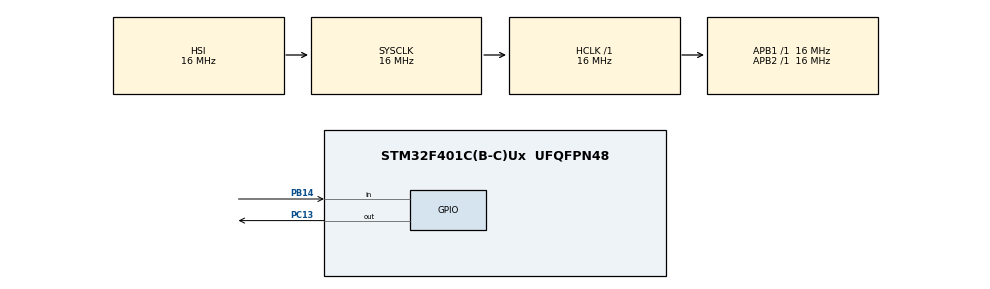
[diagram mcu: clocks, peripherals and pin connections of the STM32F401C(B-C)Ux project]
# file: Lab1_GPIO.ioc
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Mcu.Family=STM32F4
Mcu.Name=STM32F401C(B-C)Ux
Mcu.Package=UFQFPN48
NVIC.PriorityGroup=NVIC_PRIORITYGROUP_4
PB14.GPIO_PuPd=GPIO_PULLUP
PB14.Signal=GPIO_Input
PC13-ANTI_TAMP.Signal=GPIO_Output
ProjectManager.HeapSize=0x200
ProjectManager.StackSize=0x400
ProjectManager.TargetToolchain=STM32CubeIDE
RCC.AHBFreq_Value=16000000
RCC.APB1Freq_Value=16000000
RCC.APB2Freq_Value=16000000
RCC.CortexFreq_Value=16000000
RCC.HSE_VALUE=25000000
RCC.HSI_VALUE=16000000
RCC.LSE_VALUE=32768
RCC.SYSCLKFreq_VALUE=16000000
RCC.VCOOutputFreq_Value=192000000
board=custom

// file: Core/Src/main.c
/* USER CODE BEGIN Header */
/**
  ******************************************************************************
  * @file           : main.c
  * @brief          : Main program body
  ******************************************************************************
  * @attention
  *
  * Copyright (c) 2025 STMicroelectronics.
  * All rights reserved.
  *
  * This software is licensed under terms that can be found in the LICENSE file
  * in the root directory of this software component.
  * If no LICENSE file comes with this software, it is provided AS-IS.
  *
  ******************************************************************************
  */
/* USER CODE END Header */
#include "main.h"

/* USER CODE BEGIN PV */
static uint8_t mode = 0;
/* USER CODE END PV */

void SystemClock_Config(void);
static void MX_GPIO_Init(void);

int main(void)
{

  /* MCU Configuration--------------------------------------------------------*/

  /* Reset of all peripherals, Initializes the Flash interface and the Systick. */
  HAL_Init();

  /* Configure the system clock */
  SystemClock_Config();

  /* Initialize all configured peripherals */
  MX_GPIO_Init();

  /* Infinite loop */
  /* USER CODE BEGIN WHILE */
  while (1)
  {
      // читаємо стан кнопки: якщо вона натиснута, то на вході буде "0" (RESET)
      if (HAL_GPIO_ReadPin(GPIOB, GPIO_PIN_14) == GPIO_PIN_RESET) { // кнопка натиснута
          HAL_Delay(25);

          // перевіряємо чи кнопка досі натиснута після затримки
          if (HAL_GPIO_ReadPin(GPIOB, GPIO_PIN_14) == GPIO_PIN_RESET) {

              // чекаємо, поки кнопку відпустять
              while (HAL_GPIO_ReadPin(GPIOB, GPIO_PIN_14) == GPIO_PIN_RESET)
                  ; // порожній цикл

              // коли кнопку відпустили, змінюємо режим роботи світлодіода
              mode = (mode + 1) % 3; // перемикаємо режим
          }
      }

      // робота світлодіода відповідно до режиму
      switch (mode) {
          case 1: // режим 1: повільне миготіння
              HAL_GPIO_TogglePin(GPIOC, GPIO_PIN_13); // інвертуємо стан LED (ON на OFF)
              HAL_Delay(700); // повільне блимання
              break;

          case 2: // режим 2: швидке миготіння
              HAL_GPIO_TogglePin(GPIOC, GPIO_PIN_13); // інвертуємо стан LED
              HAL_Delay(120); // швидке блимання
              break;

          default: // режим 0: пауза (LED вимкнений)
              // встановлюємо постійно "1" на PC13
              // для інверсного LED це означає "вимкнути"
              HAL_GPIO_WritePin(GPIOC, GPIO_PIN_13, GPIO_PIN_SET);
              HAL_Delay(10); // пауза щоб цикл не крутився зовсім без зупинок
              break;
      }
  }

  /* USER CODE END 3 */
}

void SystemClock_Config(void)
{
  RCC_OscInitTypeDef RCC_OscInitStruct = {0};
  RCC_ClkInitTypeDef RCC_ClkInitStruct = {0};

  /** Configure the main internal regulator output voltage
  */
  __HAL_RCC_PWR_CLK_ENABLE();
  __HAL_PWR_VOLTAGESCALING_CONFIG(PWR_REGULATOR_VOLTAGE_SCALE2);

  /** Initializes the RCC Oscillators according to the specified parameters
  * in the RCC_OscInitTypeDef structure.
  */
  RCC_OscInitStruct.OscillatorType = RCC_OSCILLATORTYPE_HSI;
  RCC_OscInitStruct.HSIState = RCC_HSI_ON;
  RCC_OscInitStruct.HSICalibrationValue = RCC_HSICALIBRATION_DEFAULT;
  RCC_OscInitStruct.PLL.PLLState = RCC_PLL_NONE;
  if (HAL_RCC_OscConfig(&RCC_OscInitStruct) != HAL_OK)
  {
    Error_Handler();
  }

  /** Initializes the CPU, AHB and APB buses clocks
  */
  RCC_ClkInitStruct.ClockType = RCC_CLOCKTYPE_HCLK|RCC_CLOCKTYPE_SYSCLK
                              |RCC_CLOCKTYPE_PCLK1|RCC_CLOCKTYPE_PCLK2;
  RCC_ClkInitStruct.SYSCLKSource = RCC_SYSCLKSOURCE_HSI;
  RCC_ClkInitStruct.AHBCLKDivider = RCC_SYSCLK_DIV1;
  RCC_ClkInitStruct.APB1CLKDivider = RCC_HCLK_DIV1;
  RCC_ClkInitStruct.APB2CLKDivider = RCC_HCLK_DIV1;

  if (HAL_RCC_ClockConfig(&RCC_ClkInitStruct, FLASH_LATENCY_0) != HAL_OK)
  {
    Error_Handler();
  }
}

static void MX_GPIO_Init(void)
{
  GPIO_InitTypeDef GPIO_InitStruct = {0};

  /* GPIO Ports Clock Enable */
  __HAL_RCC_GPIOC_CLK_ENABLE();
  __HAL_RCC_GPIOB_CLK_ENABLE();

  /*Configure GPIO pin Output Level */
  HAL_GPIO_WritePin(GPIOC, GPIO_PIN_13, GPIO_PIN_RESET);

  /*Configure GPIO pin : PC13 */
  GPIO_InitStruct.Pin = GPIO_PIN_13;
  GPIO_InitStruct.Mode = GPIO_MODE_OUTPUT_PP;
  GPIO_InitStruct.Pull = GPIO_NOPULL;
  GPIO_InitStruct.Speed = GPIO_SPEED_FREQ_LOW;
  HAL_GPIO_Init(GPIOC, &GPIO_InitStruct);

  /*Configure GPIO pin : PB14 */
  GPIO_InitStruct.Pin = GPIO_PIN_14;
  GPIO_InitStruct.Mode = GPIO_MODE_INPUT;
  GPIO_InitStruct.Pull = GPIO_PULLUP;
  HAL_GPIO_Init(GPIOB, &GPIO_InitStruct);

}

void Error_Handler(void)
{
  __disable_irq();
  while (1)
  {
  }
}
